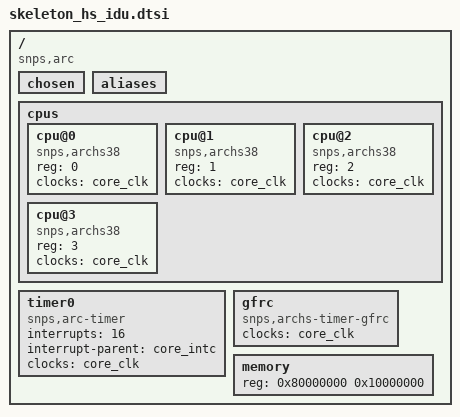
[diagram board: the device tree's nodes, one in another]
/ {
	compatible = "snps,arc";
	#address-cells = <1>;
	#size-cells = <1>;
	chosen { };
	aliases { };
	cpus {
		#address-cells = <1>;
		#size-cells = <0>;
		cpu@0 {
			device_type = "cpu";
			compatible = "snps,archs38";
			reg = <0>;
			clocks = <&core_clk>;
		};
		cpu@1 {
			device_type = "cpu";
			compatible = "snps,archs38";
			reg = <1>;
			clocks = <&core_clk>;
		};
		cpu@2 {
			device_type = "cpu";
			compatible = "snps,archs38";
			reg = <2>;
			clocks = <&core_clk>;
		};
		cpu@3 {
			device_type = "cpu";
			compatible = "snps,archs38";
			reg = <3>;
			clocks = <&core_clk>;
		};
	};
	timer0 {
		compatible = "snps,arc-timer";
		interrupts = <16>;
		interrupt-parent = <&core_intc>;
		clocks = <&core_clk>;
	};
	gfrc {
		compatible = "snps,archs-timer-gfrc";
		clocks = <&core_clk>;
	};
	memory {
		device_type = "memory";
		reg = <0x80000000 0x10000000>;	 
	};
};
